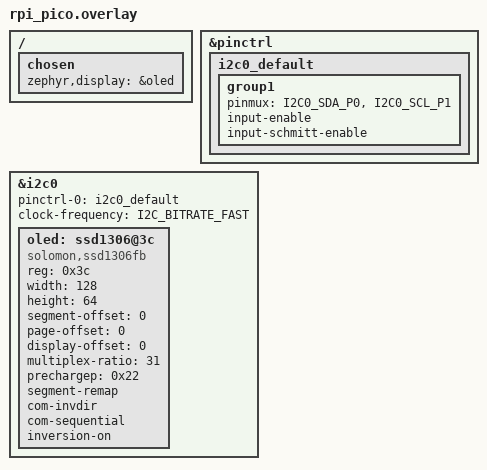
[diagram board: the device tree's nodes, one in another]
/**
 * Generated by Shield Wizard for ZMK
 * Applies to part "unibody" with controller "rpi_pico"
 */

// pin control for i2c0
// SDA on GP0
// SCL on GP1
&pinctrl {
    i2c0_default: i2c0_default {
        group1 {
            pinmux = <I2C0_SDA_P0>, <I2C0_SCL_P1>;
            input-enable;
            input-schmitt-enable;
        };
    };
};
&i2c0 {
    status = "okay";
    pinctrl-0 = <&i2c0_default>;
    pinctrl-names = "default";
    clock-frequency = <I2C_BITRATE_FAST>;
};

// devices on i2c0

&i2c0 {
    oled: ssd1306@3c {
        compatible = "solomon,ssd1306fb";
        reg = <0x3c>;
        width = <128>;
        height = <64>;

        segment-offset = <0>;
        page-offset = <0>;
        display-offset = <0>;
        multiplex-ratio = <31>;
        prechargep = <0x22>;
        segment-remap;
        com-invdir;
        com-sequential;
        inversion-on;
    };
};
/ {
    chosen {
        zephyr,display = &oled;
    };
};
